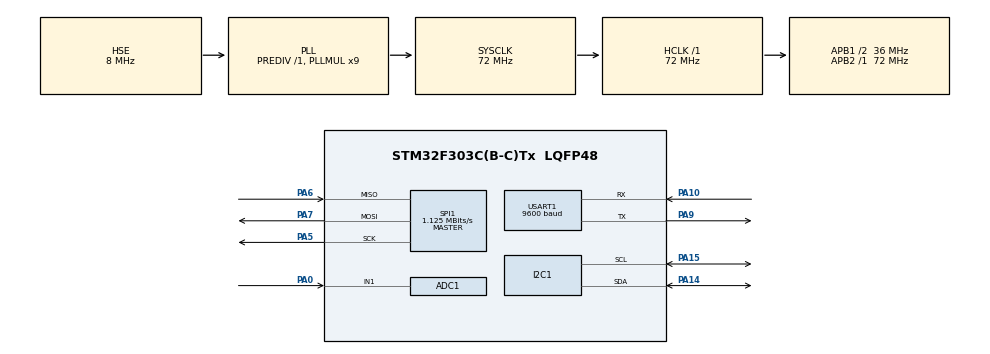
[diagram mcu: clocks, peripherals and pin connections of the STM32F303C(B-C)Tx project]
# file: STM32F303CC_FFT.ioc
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ADC1.AutoInjectedConv=DISABLE
ADC1.Channel-1\#ChannelRegularConversion=ADC_CHANNEL_1
ADC1.ClockPrescaler=ADC_CLOCK_ASYNC_DIV1
ADC1.ContinuousConvMode=ENABLE
ADC1.DMAContinuousRequests=ENABLE
ADC1.DataAlign=ADC_DATAALIGN_RIGHT
ADC1.DiscontinuousConvMode=DISABLE
ADC1.EOCSelection=ADC_EOC_SINGLE_CONV
ADC1.EnableAnalogWatchDog1=false
ADC1.EnableAnalogWatchDog2=false
ADC1.EnableAnalogWatchDog3=false
ADC1.EnableInjectedConversion=DISABLE
ADC1.EnableRegularConversion=ENABLE
ADC1.ExternalTrigConv=ADC_EXTERNALTRIGCONV_T2_TRGO
ADC1.ExternalTrigConvEdge=ADC_EXTERNALTRIGCONVEDGE_RISING
ADC1.InjectedDiscontinuousConvMode=DISABLE
ADC1.LowPowerAutoWait=DISABLE
ADC1.NbrOfConversion=1
ADC1.NbrOfConversionFlag=1
ADC1.Offset-1\#ChannelRegularConversion=0
ADC1.OffsetNumber-1\#ChannelRegularConversion=ADC_OFFSET_NONE
ADC1.Overrun=ADC_OVR_DATA_OVERWRITTEN
ADC1.Rank-1\#ChannelRegularConversion=1
ADC1.Resolution=ADC_RESOLUTION_12B
ADC1.SamplingTime-1\#ChannelRegularConversion=ADC_SAMPLETIME_1CYCLE_5
ADC1.ScanConvMode=ADC_SCAN_DISABLE
ADC1.SingleDiff-1\#ChannelRegularConversion=ADC_SINGLE_ENDED
ADC1.master=1
Dma.ADC1.0.Direction=DMA_PERIPH_TO_MEMORY
Dma.ADC1.0.Instance=DMA1_Channel1
Dma.ADC1.0.MemDataAlignment=DMA_MDATAALIGN_HALFWORD
Dma.ADC1.0.MemInc=DMA_MINC_ENABLE
Dma.ADC1.0.Mode=DMA_CIRCULAR
Dma.ADC1.0.PeriphDataAlignment=DMA_PDATAALIGN_HALFWORD
Dma.ADC1.0.PeriphInc=DMA_PINC_DISABLE
Dma.ADC1.0.Priority=DMA_PRIORITY_HIGH
Dma.Request0=ADC1
I2C1.OwnAddress2Masks=I2C_OA2_NOMASK
I2C1.Timing=0x2000090E
Mcu.Family=STM32F3
Mcu.Name=STM32F303C(B-C)Tx
Mcu.Package=LQFP48
NVIC.DMA1_Channel1_IRQn=true\:0\:0\:false\:false\:true
NVIC.PriorityGroup=NVIC_PRIORITYGROUP_4
NVIC.TIM2_IRQn=true\:0\:0\:false\:false\:true
NVIC.TIM3_IRQn=true\:0\:0\:false\:false\:true
NVIC.USART1_IRQn=true\:0\:0\:false\:false\:true
PA0.Mode=IN1-Single-Ended
PA0.Signal=ADC1_IN1
PA10.Mode=Asynchronous
PA10.Signal=USART1_RX
PA14.Mode=I2C
PA14.Signal=I2C1_SDA
PA15.Mode=I2C
PA15.Signal=I2C1_SCL
PA5.Mode=Full_Duplex_Master
PA5.Signal=SPI1_SCK
PA6.Mode=Full_Duplex_Master
PA6.Signal=SPI1_MISO
PA7.Mode=Full_Duplex_Master
PA7.Signal=SPI1_MOSI
PA9.Mode=Asynchronous
PA9.Signal=USART1_TX
PF0-OSC_IN.Mode=HSE-External-Oscillator
PF0-OSC_IN.Signal=RCC_OSC_IN
PF1-OSC_OUT.Mode=HSE-External-Oscillator
PF1-OSC_OUT.Signal=RCC_OSC_OUT
ProjectManager.HeapSize=0x200
ProjectManager.StackSize=0x400
ProjectManager.TargetToolchain=SW4STM32
RCC.ADC1Enable=true
RCC.ADC2Enable=false
RCC.ADC3Enable=false
RCC.ADC4Enable=false
RCC.AHBFreq_Value=72000000
RCC.APB1CLKDivider=RCC_HCLK_DIV2
RCC.APB1Freq_Value=36000000
RCC.APB1TimFreq_Value=72000000
RCC.APB2Freq_Value=72000000
RCC.APB2TimFreq_Value=72000000
RCC.ClockTypeHCLK=RCC_CLOCKTYPE_HCLK
RCC.ClockTypePCLK1=RCC_CLOCKTYPE_PCLK1
RCC.ClockTypePCLK2=RCC_CLOCKTYPE_PCLK2
RCC.CortexFreq_Value=72000000
RCC.EnableHSE=true
RCC.EnableHSERTCDevisor=false
RCC.EnableHSIRTCDevisor=false
RCC.EnableLSE=false
RCC.EnableLSERTC=false
RCC.EnableMCOMultDivisor=false
RCC.FLITFCLKFEnable=false
RCC.HCLKFreq_Value=72000000
RCC.HRTIMEnable=false
RCC.HSEState=RCC_HSE_ON
RCC.HSE_VALUE=8000000
RCC.HSIState=RCC_HSI_ON
RCC.HSI_VALUE=8000000
RCC.I2C1Enable=true
RCC.I2C2Enable=false
RCC.I2C3Enable=false
RCC.I2SEnable=false
RCC.IWDGEnable=false
RCC.LSE_VALUE=32768
RCC.LSIState=RCC_LSI_OFF
RCC.MCOEnable=false
RCC.OscillatorTypeHSE=RCC_OSCILLATORTYPE_HSE
RCC.OscillatorTypeHSI=RCC_OSCILLATORTYPE_HSI
RCC.PLLMUL=RCC_PLL_MUL9
RCC.PLLSource=RCC_PLLSOURCE_HSE
RCC.PLLSourceVirtual=RCC_PLLSOURCE_HSE
RCC.PLLState=RCC_PLL_ON
RCC.RCC_PERIPHCLK_I2C1Var=RCC_PERIPHCLK_I2C1
RCC.RCC_PERIPHCLK_USART1Var=RCC_PERIPHCLK_USART1
RCC.RTCEnable=false
RCC.SYSCLKFreq_VALUE=72000000
RCC.SYSCLKSource=RCC_SYSCLKSOURCE_PLLCLK
RCC.SYSCLKSourceVirtual=RCC_SYSCLKSOURCE_PLLCLK
RCC.Tim15Enable=false
RCC.Tim16Enable=false
RCC.Tim17Enable=false
RCC.Tim1Enable=false
RCC.Tim8Enable=false
RCC.UART4Enable=false
RCC.UART5Enable=false
RCC.USART1Enable=true
RCC.USART2Enable=false
RCC.USART3Enable=false
RCC.USBEnable=false
RCC.USBFreq_Value=72000000
RCC.Usart1ClockSelection=RCC_USART1CLKSOURCE_SYSCLK
SPI1.BaudRatePrescaler=SPI_BAUDRATEPRESCALER_64
SPI1.CRCLength=SPI_CRC_LENGTH_DATASIZE
SPI1.CRCPolynomial=7
SPI1.CalculateBaudRate=1.125 MBits/s
SPI1.Direction=SPI_DIRECTION_2LINES
SPI1.Mode=SPI_MODE_MASTER
SPI1.VirtualType=VM_MASTER
USART1.BaudRate=9600
USART1.HwFlowCtl-Asynchronous=UART_HWCONTROL_NONE
USART1.VirtualMode-Asynchronous=VM_ASYNC
VP_TIM2_VS_ClockSourceINT.Mode=Internal
VP_TIM3_VS_ClockSourceINT.Mode=Internal
board=STM32F303CC_FFT

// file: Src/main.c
/**
  ******************************************************************************
  * File Name          : main.c
  * Description        : Main program body
  ******************************************************************************
  *
  * COPYRIGHT(c) 2017 STMicroelectronics
  *
  * Redistribution and use in source and binary forms, with or without modification,
  * are permitted provided that the following conditions are met:
  *   1. Redistributions of source code must retain the above copyright notice,
  *      this list of conditions and the following disclaimer.
  *   2. Redistributions in binary form must reproduce the above copyright notice,
  *      this list of conditions and the following disclaimer in the documentation
  *      and/or other materials provided with the distribution.
  *   3. Neither the name of STMicroelectronics nor the names of its contributors
  *      may be used to endorse or promote products derived from this software
  *      without specific prior written permission.
  *
  * THIS SOFTWARE IS PROVIDED BY THE COPYRIGHT HOLDERS AND CONTRIBUTORS "AS IS"
  * AND ANY EXPRESS OR IMPLIED WARRANTIES, INCLUDING, BUT NOT LIMITED TO, THE
  * IMPLIED WARRANTIES OF MERCHANTABILITY AND FITNESS FOR A PARTICULAR PURPOSE ARE
  * DISCLAIMED. IN NO EVENT SHALL THE COPYRIGHT HOLDER OR CONTRIBUTORS BE LIABLE
  * FOR ANY DIRECT, INDIRECT, INCIDENTAL, SPECIAL, EXEMPLARY, OR CONSEQUENTIAL
  * DAMAGES (INCLUDING, BUT NOT LIMITED TO, PROCUREMENT OF SUBSTITUTE GOODS OR
  * SERVICES; LOSS OF USE, DATA, OR PROFITS; OR BUSINESS INTERRUPTION) HOWEVER
  * CAUSED AND ON ANY THEORY OF LIABILITY, WHETHER IN CONTRACT, STRICT LIABILITY,
  * OR TORT (INCLUDING NEGLIGENCE OR OTHERWISE) ARISING IN ANY WAY OUT OF THE USE
  * OF THIS SOFTWARE, EVEN IF ADVISED OF THE POSSIBILITY OF SUCH DAMAGE.
  *
  ******************************************************************************
  */
#include "main.h"
#include "stm32f3xx_hal.h"
#include "fft.h"

#include "arm_math.h"
#include "arm_const_structs.h"

ADC_HandleTypeDef hadc1;
DMA_HandleTypeDef hdma_adc1;

I2C_HandleTypeDef hi2c1;

SPI_HandleTypeDef hspi1;

TIM_HandleTypeDef htim2;
TIM_HandleTypeDef htim3;

UART_HandleTypeDef huart1;

/* USER CODE BEGIN PV */
/* Private variables ---------------------------------------------------------*/
int _write( int file, char *ptr, int len )
{
  HAL_UART_Transmit(&huart1,(uint8_t*) ptr, len, 1000);
  return len;
}
/* USER CODE END PV */

void SystemClock_Config(void);
void Error_Handler(void);
static void MX_GPIO_Init(void);
static void MX_DMA_Init(void);
static void MX_ADC1_Init(void);
static void MX_I2C1_Init(void);
static void MX_SPI1_Init(void);
static void MX_TIM2_Init(void);
static void MX_TIM3_Init(void);
static void MX_USART1_UART_Init(void);

/* USER CODE BEGIN PFP */
/* Private function prototypes -----------------------------------------------*/

/* USER CODE END PFP */
void HAL_ADC_ConvCpltCallback(ADC_HandleTypeDef* AdcHandle)
{

	HAL_TIM_Base_Stop_IT(&htim2);
	HAL_ADC_Stop_DMA(&hadc1);

#ifdef ENABLE_Hanning_Window

	float multiplier;
	for (int i = 0; i < LENGTH_SAMPLES/2; i++) {
		multiplier = 0.5 * (1 - arm_cos_f32(2.0*PI*i/(LENGTH_SAMPLES/2-1)));
		g_ADCBuffer[i] = multiplier * g_ADCBuffer[i];
	}
#endif

	for(int i=0;i<LENGTH_SAMPLES/2;i++){
		int tmp;
		tmp= g_ADCBuffer[i];
		FFT_Input[2*i]=tmp;
	    FFT_Input[2*i+1]=0.0;
	}

	fft_status=RUN;
	//printf("HAL_ADC_ConvCpltCallback \n");
}

void HAL_TIM_PeriodElapsedCallback(TIM_HandleTypeDef *htim)
{

	if (htim->Instance==TIM2)
      {
		//HAL_GPIO_TogglePin(GPIOA,GPIO_PIN_4);
		//printf("HAL_TIM_PeriodElapsedCallback \n");

      }

}

int main(void)
{

  /* MCU Configuration----------------------------------------------------------*/

  /* Reset of all peripherals, Initializes the Flash interface and the Systick. */
  HAL_Init();

  /* Configure the system clock */
  SystemClock_Config();

  /* Initialize all configured peripherals */
  MX_GPIO_Init();
  MX_DMA_Init();
  MX_ADC1_Init();
  MX_I2C1_Init();
  MX_SPI1_Init();
  MX_TIM2_Init();
  MX_TIM3_Init();
  MX_USART1_UART_Init();

   /* USER CODE BEGIN 2 */
  printf("Initialize Success!!\n");
  printf("SYS Clock: %d MHz \n", (int)(SystemCoreClock / 1000000) );
  Init_dsp_FFT();
  printf("Start ADC & Timer!!\n");
  /* USER CODE END 2 */

  /* Infinite loop */
  while (1)
  {
	  if(fft_status==RUN){
		  Exec_dsp_FFT();
		  HAL_Delay(300);
		  ReStartAdcDma();
	  }
	  __asm volatile("nop");
	  //printf("While...\n\r");
	  //HAL_Delay(300);
  }

}

/** System Clock Configuration
*/
void SystemClock_Config(void)
{

  RCC_OscInitTypeDef RCC_OscInitStruct;
  RCC_ClkInitTypeDef RCC_ClkInitStruct;
  RCC_PeriphCLKInitTypeDef PeriphClkInit;

    /**Initializes the CPU, AHB and APB busses clocks
    */
  RCC_OscInitStruct.OscillatorType = RCC_OSCILLATORTYPE_HSI|RCC_OSCILLATORTYPE_HSE;
  RCC_OscInitStruct.HSEState = RCC_HSE_ON;
  RCC_OscInitStruct.HSEPredivValue = RCC_HSE_PREDIV_DIV1;
  RCC_OscInitStruct.HSIState = RCC_HSI_ON;
  RCC_OscInitStruct.HSICalibrationValue = 16;
  RCC_OscInitStruct.PLL.PLLState = RCC_PLL_ON;
  RCC_OscInitStruct.PLL.PLLSource = RCC_PLLSOURCE_HSE;
  RCC_OscInitStruct.PLL.PLLMUL = RCC_PLL_MUL9;
  if (HAL_RCC_OscConfig(&RCC_OscInitStruct) != HAL_OK)
  {
    Error_Handler();
  }

    /**Initializes the CPU, AHB and APB busses clocks
    */
  RCC_ClkInitStruct.ClockType = RCC_CLOCKTYPE_HCLK|RCC_CLOCKTYPE_SYSCLK
                              |RCC_CLOCKTYPE_PCLK1|RCC_CLOCKTYPE_PCLK2;
  RCC_ClkInitStruct.SYSCLKSource = RCC_SYSCLKSOURCE_PLLCLK;
  RCC_ClkInitStruct.AHBCLKDivider = RCC_SYSCLK_DIV1;//RCC_SYSCLK_DIV2//1
  RCC_ClkInitStruct.APB1CLKDivider = RCC_HCLK_DIV2;//RCC_HCLK_DIV1;//2
  RCC_ClkInitStruct.APB2CLKDivider = RCC_HCLK_DIV1;

  if (HAL_RCC_ClockConfig(&RCC_ClkInitStruct, FLASH_LATENCY_1) != HAL_OK)
  {
    Error_Handler();
  }

  PeriphClkInit.PeriphClockSelection = RCC_PERIPHCLK_USART1|RCC_PERIPHCLK_I2C1
                              |RCC_PERIPHCLK_ADC12;
  PeriphClkInit.Usart1ClockSelection = RCC_USART1CLKSOURCE_SYSCLK;
  PeriphClkInit.Adc12ClockSelection = RCC_ADC12PLLCLK_DIV1;
  PeriphClkInit.I2c1ClockSelection = RCC_I2C1CLKSOURCE_HSI;
  if (HAL_RCCEx_PeriphCLKConfig(&PeriphClkInit) != HAL_OK)
  {
    Error_Handler();
  }

    /**Configure the Systick interrupt time
    */
  HAL_SYSTICK_Config(HAL_RCC_GetHCLKFreq()/1000);

    /**Configure the Systick
    */
  HAL_SYSTICK_CLKSourceConfig(SYSTICK_CLKSOURCE_HCLK);

  /* SysTick_IRQn interrupt configuration */
  HAL_NVIC_SetPriority(SysTick_IRQn, 0, 0);
}

/* ADC1 init function */
static void MX_ADC1_Init(void)
{

  ADC_ChannelConfTypeDef sConfig;

    /**Common config
    */
  hadc1.Instance = ADC1;
  hadc1.Init.ClockPrescaler = ADC_CLOCK_ASYNC_DIV1;
  hadc1.Init.Resolution = ADC_RESOLUTION_12B;
  hadc1.Init.ScanConvMode = ADC_SCAN_DISABLE;
  hadc1.Init.ContinuousConvMode = DISABLE;//
  hadc1.Init.DiscontinuousConvMode = ENABLE;//
  hadc1.Init.ExternalTrigConvEdge = ADC_EXTERNALTRIGCONVEDGE_RISING;
  hadc1.Init.ExternalTrigConv = ADC_EXTERNALTRIGCONV_T2_TRGO;
  hadc1.Init.DataAlign = ADC_DATAALIGN_RIGHT;
  hadc1.Init.NbrOfConversion = 1;
  hadc1.Init.DMAContinuousRequests = DISABLE;//
  hadc1.Init.EOCSelection = ADC_EOC_SINGLE_CONV;
  hadc1.Init.LowPowerAutoWait = DISABLE;
  hadc1.Init.Overrun = ADC_OVR_DATA_PRESERVED;//
  if (HAL_ADC_Init(&hadc1) != HAL_OK)
  {
    Error_Handler();
  }

    /**Configure Regular Channel
    */
  sConfig.Channel = ADC_CHANNEL_1;
  sConfig.Rank = 1;
  sConfig.SingleDiff = ADC_SINGLE_ENDED;
  sConfig.SamplingTime = ADC_SAMPLETIME_61CYCLES_5;//ADC_SAMPLETIME_61CYCLES_5;//ADC_SAMPLETIME_19CYCLES_5;//
  sConfig.OffsetNumber = ADC_OFFSET_NONE;
  sConfig.Offset = 0;
  if (HAL_ADC_ConfigChannel(&hadc1, &sConfig) != HAL_OK)
  {
    Error_Handler();
  }

}

/* I2C1 init function */
static void MX_I2C1_Init(void)
{

  hi2c1.Instance = I2C1;
  hi2c1.Init.Timing = 0x2000090E;
  hi2c1.Init.OwnAddress1 = 0;
  hi2c1.Init.AddressingMode = I2C_ADDRESSINGMODE_7BIT;
  hi2c1.Init.DualAddressMode = I2C_DUALADDRESS_DISABLE;
  hi2c1.Init.OwnAddress2 = 0;
  hi2c1.Init.OwnAddress2Masks = I2C_OA2_NOMASK;
  hi2c1.Init.GeneralCallMode = I2C_GENERALCALL_DISABLE;
  hi2c1.Init.NoStretchMode = I2C_NOSTRETCH_DISABLE;
  if (HAL_I2C_Init(&hi2c1) != HAL_OK)
  {
    Error_Handler();
  }

    /**Configure Analogue filter
    */
  if (HAL_I2CEx_ConfigAnalogFilter(&hi2c1, I2C_ANALOGFILTER_ENABLE) != HAL_OK)
  {
    Error_Handler();
  }

}

/* SPI1 init function */
static void MX_SPI1_Init(void)
{

  hspi1.Instance = SPI1;
  hspi1.Init.Mode = SPI_MODE_MASTER;
  hspi1.Init.Direction = SPI_DIRECTION_2LINES;
  hspi1.Init.DataSize = SPI_DATASIZE_4BIT;
  hspi1.Init.CLKPolarity = SPI_POLARITY_LOW;
  hspi1.Init.CLKPhase = SPI_PHASE_1EDGE;
  hspi1.Init.NSS = SPI_NSS_SOFT;
  hspi1.Init.BaudRatePrescaler = SPI_BAUDRATEPRESCALER_32;//SPI_BAUDRATEPRESCALER_2;
  hspi1.Init.FirstBit = SPI_FIRSTBIT_MSB;
  hspi1.Init.TIMode = SPI_TIMODE_DISABLE;
  hspi1.Init.CRCCalculation = SPI_CRCCALCULATION_DISABLE;
  hspi1.Init.CRCPolynomial = 7;
  hspi1.Init.CRCLength = SPI_CRC_LENGTH_DATASIZE;
  hspi1.Init.NSSPMode = SPI_NSS_PULSE_ENABLE;
  if (HAL_SPI_Init(&hspi1) != HAL_OK)
  {
    Error_Handler();
  }

}

/* TIM2 init function */
static void MX_TIM2_Init(void)
{

  TIM_ClockConfigTypeDef sClockSourceConfig;
  TIM_MasterConfigTypeDef sMasterConfig;

  htim2.Instance = TIM2;
  htim2.Init.Prescaler = (SystemCoreClock / 1000000) - 1;//56-1;
    htim2.Init.CounterMode = TIM_COUNTERMODE_UP;
    htim2.Init.Period = 9;//1000000/(SMP_kHz*1000)-1;//10-1;//10-1;
  htim2.Init.ClockDivision = TIM_CLOCKDIVISION_DIV1;
  if (HAL_TIM_Base_Init(&htim2) != HAL_OK)
  {
    Error_Handler();
  }

  sClockSourceConfig.ClockSource = TIM_CLOCKSOURCE_INTERNAL;
  if (HAL_TIM_ConfigClockSource(&htim2, &sClockSourceConfig) != HAL_OK)
  {
    Error_Handler();
  }

  sMasterConfig.MasterOutputTrigger = TIM_TRGO_UPDATE;//TIM_TRGO_RESET;
  sMasterConfig.MasterSlaveMode = TIM_MASTERSLAVEMODE_DISABLE;
  if (HAL_TIMEx_MasterConfigSynchronization(&htim2, &sMasterConfig) != HAL_OK)
  {
    Error_Handler();
  }

}

/* TIM3 init function */
static void MX_TIM3_Init(void)
{

  TIM_ClockConfigTypeDef sClockSourceConfig;
  TIM_MasterConfigTypeDef sMasterConfig;

  htim3.Instance = TIM3;
  htim3.Init.Prescaler = 0;
  htim3.Init.CounterMode = TIM_COUNTERMODE_UP;
  htim3.Init.Period = 0;
  htim3.Init.ClockDivision = TIM_CLOCKDIVISION_DIV1;
  if (HAL_TIM_Base_Init(&htim3) != HAL_OK)
  {
    Error_Handler();
  }

  sClockSourceConfig.ClockSource = TIM_CLOCKSOURCE_INTERNAL;
  if (HAL_TIM_ConfigClockSource(&htim3, &sClockSourceConfig) != HAL_OK)
  {
    Error_Handler();
  }

  sMasterConfig.MasterOutputTrigger = TIM_TRGO_RESET;
  sMasterConfig.MasterSlaveMode = TIM_MASTERSLAVEMODE_DISABLE;
  if (HAL_TIMEx_MasterConfigSynchronization(&htim3, &sMasterConfig) != HAL_OK)
  {
    Error_Handler();
  }

}

/* USART1 init function */
static void MX_USART1_UART_Init(void)
{

  huart1.Instance = USART1;
  huart1.Init.BaudRate = 9600;
  huart1.Init.WordLength = UART_WORDLENGTH_8B;
  huart1.Init.StopBits = UART_STOPBITS_1;
  huart1.Init.Parity = UART_PARITY_NONE;
  huart1.Init.Mode = UART_MODE_TX_RX;
  huart1.Init.HwFlowCtl = UART_HWCONTROL_NONE;
  huart1.Init.OverSampling = UART_OVERSAMPLING_16;
  huart1.Init.OneBitSampling = UART_ONE_BIT_SAMPLE_DISABLE;
  huart1.AdvancedInit.AdvFeatureInit = UART_ADVFEATURE_NO_INIT;
  if (HAL_UART_Init(&huart1) != HAL_OK)
  {
    Error_Handler();
  }

}

static void MX_DMA_Init(void)
{
  /* DMA controller clock enable */
  __HAL_RCC_DMA1_CLK_ENABLE();

  /* DMA interrupt init */
  /* DMA1_Channel1_IRQn interrupt configuration */
  HAL_NVIC_SetPriority(DMA1_Channel1_IRQn, 0, 0);
  HAL_NVIC_EnableIRQ(DMA1_Channel1_IRQn);

}

/** Configure pins as
        * Analog
        * Input
        * Output
        * EVENT_OUT
        * EXTI
*/
static void MX_GPIO_Init(void)
{

  /* GPIO Ports Clock Enable */
  __HAL_RCC_GPIOF_CLK_ENABLE();
  __HAL_RCC_GPIOA_CLK_ENABLE();

}

void Error_Handler(void)
{
  while(1)
  {
  }
}

/************************ (C) COPYRIGHT STMicroelectronics *****END OF FILE****/
